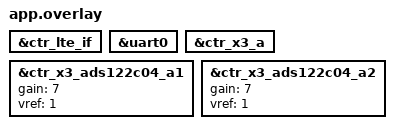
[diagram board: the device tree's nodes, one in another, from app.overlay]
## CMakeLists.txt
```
#
# Copyright (c) 2024 HARDWARIO a.s.
#
#  SPDX-License-Identifier: LicenseRef-HARDWARIO-5-Clause
#

cmake_minimum_required(VERSION 3.20.0)

set(ENV{FW_BUNDLE} "com.hardwario.chester.scale")
set(ENV{FW_VERSION} "v1.0.0")
set(ENV{FW_NAME} "CHESTER Scale")

find_package(Zephyr REQUIRED HINTS $ENV{ZEPHYR_BASE})

project(chester-scale)

target_sources(app PRIVATE src/main.c)
target_sources(app PRIVATE src/app_shell.c)
target_sources(app PRIVATE src/app_loop.c)
target_sources(app PRIVATE src/app_init.c)
target_sources(app PRIVATE src/app_data.c)
target_sources(app PRIVATE src/app_send.c)
target_sources(app PRIVATE src/app_config.c)
target_sources(app PRIVATE src/app_handler.c)
target_sources(app PRIVATE src/app_measure.c)
target_sources(app PRIVATE src/app_cbor.c)
```

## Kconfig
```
#
# Copyright (c) 2024 HARDWARIO a.s.
#
# SPDX-License-Identifier: LicenseRef-HARDWARIO-5-Clause
#

menu "Application"

# CHESTER SCALE Project | SCALE Variant 

# LTE 
config SHIELD_CTR_LTE
	bool "Enable SHIELD_CTR_LTE"
	default y 

config CTR_LTE
	default y
# X3_A 
config SHIELD_CTR_CTR_X3_A
	bool "Enable SHIELD_CTR_X3_A"
	default y 

config CTR_X3
	default y

endmenu

menu "Zephyr Kernel"
source "Kconfig.zephyr"
endmenu
```

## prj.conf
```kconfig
#
# Copyright (c) 2024 HARDWARIO a.s.
#
#  SPDX-License-Identifier: LicenseRef-HARDWARIO-5-Clause
#

# Configurations
CONFIG_ADC_SHELL=y
CONFIG_CTR_ACCEL=y
CONFIG_CTR_BATT=y
CONFIG_CTR_BLE=y
CONFIG_CTR_BUTTON=y
CONFIG_CTR_BUF=y
CONFIG_CTR_DEFAULTS=y
CONFIG_CTR_INFO=y
CONFIG_CTR_LED=y
CONFIG_CTR_LOG=y
CONFIG_CTR_RTC=y
CONFIG_CTR_THERM=y
CONFIG_CTR_WDOG=y
CONFIG_ENTROPY_GENERATOR=y
CONFIG_TINYCRYPT=y
CONFIG_TINYCRYPT_SHA256=y
CONFIG_ZCBOR=y
CONFIG_ZCBOR_STOP_ON_ERROR=y
CONFIG_CTR_LTE_CLKSYNC=y

# Extra configurations
CONFIG_ADC_TLA2021_INIT_PRIORITY=60
CONFIG_ADC_NRFX_SAADC=n
CONFIG_ADC_SHELL=n

# USER CODE BEGIN Config 
# USER CODE END Config
```

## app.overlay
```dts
/*
 * Copyright (c) 2024 HARDWARIO a.s.
 *
 * SPDX-License-Identifier: LicenseRef-HARDWARIO-5-Clause
 */

/* CHESTER SCALE Project | SCALE Variant */

/* LTE  */
&ctr_lte_if {
	status = "okay";
};

&uart0 {
	status = "okay";
};
/* X3_A  */
&ctr_x3_a {
	status = "okay";
};

&ctr_x3_ads122c04_a1 {
	status = "okay";
	gain = <7>;
	vref = <1>;
};

&ctr_x3_ads122c04_a2 {
	status = "okay";
	gain = <7>;
	vref = <1>;
};
```

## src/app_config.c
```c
/*
 * Copyright (c) 2024 HARDWARIO a.s.
 *
 * SPDX-License-Identifier: LicenseRef-HARDWARIO-5-Clause
 */

#include "app_config.h"

/* CHESTER includes */
#include <chester/ctr_config.h>

/* Zephyr includes */
#include <zephyr/init.h>
#include <zephyr/kernel.h>
#include <zephyr/logging/log.h>
#include <zephyr/settings/settings.h>
#include <zephyr/shell/shell.h>

/* Standard includes */
#include <ctype.h>
#include <stdbool.h>
#include <stdio.h>
#include <stdlib.h>
#include <string.h>

/* USER CODE BEGIN Includes */
/* USER CODE END Includes */

LOG_MODULE_REGISTER(app_config, LOG_LEVEL_DBG);

#define SETTINGS_PFX "chester-scale"

struct app_config g_app_config;

static struct app_config m_app_config_interim = {
	.channel_a1_active = true,
	.channel_a2_active = true,
	.channel_b1_active = true,
	.channel_b2_active = true,
	.weight_measurement_interval = 60,
	.report_interval = 900,
	.people_measurement_interval = 600,
	.people_counter_power_off_delay = 30,
	.people_counter_stay_timeout = 5,
	.people_counter_adult_border = 4,

	/* USER CODE BEGIN Struct Variables */
	/* USER CODE END Struct Variables */
};

/* USER CODE BEGIN Variables */
/* USER CODE END Variables */

static void print_channel_a1_active(const struct shell *shell)
{
	shell_print(shell, "app config channel-a1-active  %s",
			m_app_config_interim.channel_a1_active ? "true" : "false");
}

int app_config_cmd_config_channel_a1_active(const struct shell *shell, size_t argc, char **argv)
{
	if (argc == 1) {
		print_channel_a1_active(shell);                                                    
		return 0;
	}
	if (argc == 2) {
		bool is_false = !strcmp(argv[1], "false");
		bool is_true = !strcmp(argv[1], "true");
		if (is_false) {
			m_app_config_interim.channel_a1_active = false;
		} else if (is_true) {
			m_app_config_interim.channel_a1_active = true;
		} else {
			shell_error(shell, "invalid format");
			return -EINVAL;
		}
		return 0;
	}
	shell_help(shell);
	return -EINVAL;
}

static void print_channel_a2_active(const struct shell *shell)
{
	shell_print(shell, "app config channel-a2-active  %s",
			m_app_config_interim.channel_a2_active ? "true" : "false");
}

int app_config_cmd_config_channel_a2_active(const struct shell *shell, size_t argc, char **argv)
{
	if (argc == 1) {
		print_channel_a2_active(shell);                                                    
		return 0;
	}
	if (argc == 2) {
		bool is_false = !strcmp(argv[1], "false");
		bool is_true = !strcmp(argv[1], "true");
		if (is_false) {
			m_app_config_interim.channel_a2_active = false;
		} else if (is_true) {
			m_app_config_interim.channel_a2_active = true;
		} else {
			shell_error(shell, "invalid format");
			return -EINVAL;
		}
		return 0;
	}
	shell_help(shell);
	return -EINVAL;
}

static void print_channel_b1_active(const struct shell *shell)
{
	shell_print(shell, "app config channel-b1-active  %s",
			m_app_config_interim.channel_b1_active ? "true" : "false");
}

int app_config_cmd_config_channel_b1_active(const struct shell *shell, size_t argc, char **argv)
{
	if (argc == 1) {
		print_channel_b1_active(shell);                                                    
		return 0;
	}
	if (argc == 2) {
		bool is_false = !strcmp(argv[1], "false");
		bool is_true = !strcmp(argv[1], "true");
		if (is_false) {
			m_app_config_interim.channel_b1_active = false;
		} else if (is_true) {
			m_app_config_interim.channel_b1_active = true;
		} else {
			shell_error(shell, "invalid format");
			return -EINVAL;
		}
		return 0;
	}
	shell_help(shell);
	return -EINVAL;
}

static void print_channel_b2_active(const struct shell *shell)
{
	shell_print(shell, "app config channel-b2-active  %s",
			m_app_config_interim.channel_b2_active ? "true" : "false");
}

int app_config_cmd_config_channel_b2_active(const struct shell *shell, size_t argc, char **argv)
{
	if (argc == 1) {
		print_channel_b2_active(shell);                                                    
		return 0;
	}
	if (argc == 2) {
		bool is_false = !strcmp(argv[1], "false");
		bool is_true = !strcmp(argv[1], "true");
		if (is_false) {
			m_app_config_interim.channel_b2_active = false;
		} else if (is_true) {
			m_app_config_interim.channel_b2_active = true;
		} else {
			shell_error(shell, "invalid format");
			return -EINVAL;
		}
		return 0;
	}
	shell_help(shell);
	return -EINVAL;
}

static void print_weight_measurement_interval(const struct shell *shell)
{
	shell_print(shell, "app config weight-measurement-interval  %d",
			m_app_config_interim.weight_measurement_interval);
}

int app_config_cmd_config_weight_measurement_interval(const struct shell *shell, size_t argc, char **argv)
{
	if (argc == 1) {
		print_weight_measurement_interval(shell);
		return 0;
	}
	if (argc == 2) {
		size_t len = strlen(argv[1]);
		for (size_t i = 0; i < len; i++) {
			if (!isdigit((int)argv[1][i])) {
				shell_error(shell, "invalid format");
				return -EINVAL;
			}
		}
		long value = strtol(argv[1], NULL, 10);
		if (value < 5 || value > 3600) {
			shell_error(shell, "invalid range");
			return -EINVAL;
		}
		m_app_config_interim.weight_measurement_interval = (int)value;
		return 0;
	}
	shell_help(shell);
	return -EINVAL;
}

static void print_report_interval(const struct shell *shell)
{
	shell_print(shell, "app config report-interval  %d",
			m_app_config_interim.report_interval);
}

int app_config_cmd_config_report_interval(const struct shell *shell, size_t argc, char **argv)
{
	if (argc == 1) {
		print_report_interval(shell);
		return 0;
	}
	if (argc == 2) {
		size_t len = strlen(argv[1]);
		for (size_t i = 0; i < len; i++) {
			if (!isdigit((int)argv[1][i])) {
				shell_error(shell, "invalid format");
				return -EINVAL;
			}
		}
		long value = strtol(argv[1], NULL, 10);
		if (value < 30 || value > 86400) {
			shell_error(shell, "invalid range");
			return -EINVAL;
		}
		m_app_config_interim.report_interval = (int)value;
		return 0;
	}
	shell_help(shell);
	return -EINVAL;
}

static void print_people_measurement_interval(const struct shell *shell)
{
	shell_print(shell, "app config people-measurement-interval  %d",
			m_app_config_interim.people_measurement_interval);
}

int app_config_cmd_config_people_measurement_interval(const struct shell *shell, size_t argc, char **argv)
{
	if (argc == 1) {
		print_people_measurement_interval(shell);
		return 0;
	}
	if (argc == 2) {
		size_t len = strlen(argv[1]);
		for (size_t i = 0; i < len; i++) {
			if (!isdigit((int)argv[1][i])) {
				shell_error(shell, "invalid format");
				return -EINVAL;
			}
		}
		long value = strtol(argv[1], NULL, 10);
		if (value < 5 || value > 3600) {
			shell_error(shell, "invalid range");
			return -EINVAL;
		}
		m_app_config_interim.people_measurement_interval = (int)value;
		return 0;
	}
	shell_help(shell);
	return -EINVAL;
}

static void print_people_counter_power_off_delay(const struct shell *shell)
{
	shell_print(shell, "app config people-counter-power-off-delay  %d",
			m_app_config_interim.people_counter_power_off_delay);
}

int app_config_cmd_config_people_counter_power_off_delay(const struct shell *shell, size_t argc, char **argv)
{
	if (argc == 1) {
		print_people_counter_power_off_delay(shell);
		return 0;
	}
	if (argc == 2) {
		size_t len = strlen(argv[1]);
		for (size_t i = 0; i < len; i++) {
			if (!isdigit((int)argv[1][i])) {
				shell_error(shell, "invalid format");
				return -EINVAL;
			}
		}
		long value = strtol(argv[1], NULL, 10);
		if (value < 0 || value > 255) {
			shell_error(shell, "invalid range");
			return -EINVAL;
		}
		m_app_config_interim.people_counter_power_off_delay = (int)value;
		return 0;
	}
	shell_help(shell);
	return -EINVAL;
}

static void print_people_counter_stay_timeout(const struct shell *shell)
{
	shell_print(shell, "app config people-counter-stay-timeout  %d",
			m_app_config_interim.people_counter_stay_timeout);
}

int app_config_cmd_config_people_counter_stay_timeout(const struct shell *shell, size_t argc, char **argv)
{
	if (argc == 1) {
		print_people_counter_stay_timeout(shell);
		return 0;
	}
	if (argc == 2) {
		size_t len = strlen(argv[1]);
		for (size_t i = 0; i < len; i++) {
			if (!isdigit((int)argv[1][i])) {
				shell_error(shell, "invalid format");
				return -EINVAL;
			}
		}
		long value = strtol(argv[1], NULL, 10);
		if (value < 0 || value > 255) {
			shell_error(shell, "invalid range");
			return -EINVAL;
		}
		m_app_config_interim.people_counter_stay_timeout = (int)value;
		return 0;
	}
	shell_help(shell);
	return -EINVAL;
}

static void print_people_counter_adult_border(const struct shell *shell)
{
	shell_print(shell, "app config people-counter-adult-border  %d",
			m_app_config_interim.people_counter_adult_border);
}

int app_config_cmd_config_people_counter_adult_border(const struct shell *shell, size_t argc, char **argv)
{
	if (argc == 1) {
		print_people_counter_adult_border(shell);
		return 0;
	}
	if (argc == 2) {
		size_t len = strlen(argv[1]);
		for (size_t i = 0; i < len; i++) {
			if (!isdigit((int)argv[1][i])) {
				shell_error(shell, "invalid format");
				return -EINVAL;
			}
		}
		long value = strtol(argv[1], NULL, 10);
		if (value < 0 || value > 8) {
			shell_error(shell, "invalid range");
			return -EINVAL;
		}
		m_app_config_interim.people_counter_adult_border = (int)value;
		return 0;
	}
	shell_help(shell);
	return -EINVAL;
}

int app_config_cmd_config_show(const struct shell *shell, size_t argc, char **argv)
{
	print_channel_a1_active(shell);
	print_channel_a2_active(shell);
	print_channel_b1_active(shell);
	print_channel_b2_active(shell);
	print_weight_measurement_interval(shell);
	print_report_interval(shell);
	print_people_measurement_interval(shell);
	print_people_counter_power_off_delay(shell);
	print_people_counter_stay_timeout(shell);
	print_people_counter_adult_border(shell);
	
	return 0;
}

/* USER CODE BEGIN Functions 1 */
/* USER CODE END Functions 1 */

static int h_commit(void)
{
	LOG_DBG("Loaded settings in full");
	memcpy(&g_app_config, &m_app_config_interim, sizeof(g_app_config));

	return 0;
}

static int h_set(const char *key, size_t len, settings_read_cb read_cb, void *cb_arg) 
{
	int ret;
	const char *next;
	if (settings_name_steq(key, "channel-a1-active", &next) && !next) {
		if (len != sizeof(m_app_config_interim.channel_a1_active)) {
			return -EINVAL;
		}
		ret = read_cb(cb_arg, &m_app_config_interim.channel_a1_active, len);
		if (ret < 0) {
			LOG_ERR("Call `read_cb` failed: %d", ret);
			return ret;
		}
		return 0;
	}

	if (settings_name_steq(key, "channel-a2-active", &next) && !next) {
		if (len != sizeof(m_app_config_interim.channel_a2_active)) {
			return -EINVAL;
		}
		ret = read_cb(cb_arg, &m_app_config_interim.channel_a2_active, len);
		if (ret < 0) {
			LOG_ERR("Call `read_cb` failed: %d", ret);
			return ret;
		}
		return 0;
	}

	if (settings_name_steq(key, "channel-b1-active", &next) && !next) {
		if (len != sizeof(m_app_config_interim.channel_b1_active)) {
			return -EINVAL;
		}
		ret = read_cb(cb_arg, &m_app_config_interim.channel_b1_active, len);
		if (ret < 0) {
			LOG_ERR("Call `read_cb` failed: %d", ret);
			return ret;
		}
		return 0;
	}

	if (settings_name_steq(key, "channel-b2-active", &next) && !next) {
		if (len != sizeof(m_app_config_interim.channel_b2_active)) {
			return -EINVAL;
		}
		ret = read_cb(cb_arg, &m_app_config_interim.channel_b2_active, len);
		if (ret < 0) {
			LOG_ERR("Call `read_cb` failed: %d", ret);
			return ret;
		}
		return 0;
	}

	if (settings_name_steq(key, "weight-measurement-interval", &next) && !next) {
		if (len != sizeof(m_app_config_interim.weight_measurement_interval)) {
			return -EINVAL;
		}
		ret = read_cb(cb_arg, &m_app_config_interim.weight_measurement_interval, len);
		if (ret < 0) {
			LOG_ERR("Call `read_cb` failed: %d", ret);
			return ret;
		}
		return 0;
	}

	if (settings_name_steq(key, "report-interval", &next) && !next) {
		if (len != sizeof(m_app_config_interim.report_interval)) {
			return -EINVAL;
		}
		ret = read_cb(cb_arg, &m_app_config_interim.report_interval, len);
		if (ret < 0) {
			LOG_ERR("Call `read_cb` failed: %d", ret);
			return ret;
		}
		return 0;
	}

	if (settings_name_steq(key, "people-measurement-interval", &next) && !next) {
		if (len != sizeof(m_app_config_interim.people_measurement_interval)) {
			return -EINVAL;
		}
		ret = read_cb(cb_arg, &m_app_config_interim.people_measurement_interval, len);
		if (ret < 0) {
			LOG_ERR("Call `read_cb` failed: %d", ret);
			return ret;
		}
		return 0;
	}

	if (settings_name_steq(key, "people-counter-power-off-delay", &next) && !next) {
		if (len != sizeof(m_app_config_interim.people_counter_power_off_delay)) {
			return -EINVAL;
		}
		ret = read_cb(cb_arg, &m_app_config_interim.people_counter_power_off_delay, len);
		if (ret < 0) {
			LOG_ERR("Call `read_cb` failed: %d", ret);
			return ret;
		}
		return 0;
	}

	if (settings_name_steq(key, "people-counter-stay-timeout", &next) && !next) {
		if (len != sizeof(m_app_config_interim.people_counter_stay_timeout)) {
			return -EINVAL;
		}
		ret = read_cb(cb_arg, &m_app_config_interim.people_counter_stay_timeout, len);
		if (ret < 0) {
			LOG_ERR("Call `read_cb` failed: %d", ret);
			return ret;
		}
		return 0;
	}

	if (settings_name_steq(key, "people-counter-adult-border", &next) && !next) {
		if (len != sizeof(m_app_config_interim.people_counter_adult_border)) {
			return -EINVAL;
		}
		ret = read_cb(cb_arg, &m_app_config_interim.people_counter_adult_border, len);
		if (ret < 0) {
			LOG_ERR("Call `read_cb` failed: %d", ret);
			return ret;
		}
		return 0;
	}

	/* USER CODE BEGIN Functions 2 */
	/* USER CODE END Functions 2 */

	return 0;
}

static int h_export(int (*export_func)(const char *name, const void *val, size_t val_len))
{
	int ret;

	ret = export_func("chester-scale/channel-a1-active", &m_app_config_interim.channel_a1_active,
					  sizeof( m_app_config_interim.channel_a1_active));
	if (ret < 0) {
		return ret;
	}

	ret = export_func("chester-scale/channel-a2-active", &m_app_config_interim.channel_a2_active,
					  sizeof( m_app_config_interim.channel_a2_active));
	if (ret < 0) {
		return ret;
	}

	ret = export_func("chester-scale/channel-b1-active", &m_app_config_interim.channel_b1_active,
					  sizeof( m_app_config_interim.channel_b1_active));
	if (ret < 0) {
		return ret;
	}

	ret = export_func("chester-scale/channel-b2-active", &m_app_config_interim.channel_b2_active,
					  sizeof( m_app_config_interim.channel_b2_active));
	if (ret < 0) {
		return ret;
	}

	ret = export_func("chester-scale/weight-measurement-interval", &m_app_config_interim.weight_measurement_interval,
					  sizeof( m_app_config_interim.weight_measurement_interval));
	if (ret < 0) {
		return ret;
	}

	ret = export_func("chester-scale/report-interval", &m_app_config_interim.report_interval,
					  sizeof( m_app_config_interim.report_interval));
	if (ret < 0) {
		return ret;
	}

	ret = export_func("chester-scale/people-measurement-interval", &m_app_config_interim.people_measurement_interval,
					  sizeof( m_app_config_interim.people_measurement_interval));
	if (ret < 0) {
		return ret;
	}

	ret = export_func("chester-scale/people-counter-power-off-delay", &m_app_config_interim.people_counter_power_off_delay,
					  sizeof( m_app_config_interim.people_counter_power_off_delay));
	if (ret < 0) {
		return ret;
	}

	ret = export_func("chester-scale/people-counter-stay-timeout", &m_app_config_interim.people_counter_stay_timeout,
					  sizeof( m_app_config_interim.people_counter_stay_timeout));
	if (ret < 0) {
		return ret;
	}

	ret = export_func("chester-scale/people-counter-adult-border", &m_app_config_interim.people_counter_adult_border,
					  sizeof( m_app_config_interim.people_counter_adult_border));
	if (ret < 0) {
		return ret;
	}

	/* USER CODE BEGIN Functions 3 */
	/* USER CODE END Functions 3 */

	return 0;
}

static int init(void) 
{
	int ret;

	LOG_INF("System initialization");

	static struct settings_handler sh = {
		.name = SETTINGS_PFX,
		.h_set = h_set,
		.h_commit = h_commit,
		.h_export = h_export,
	};

	ret = settings_register(&sh);

	if (ret < 0) {
		LOG_ERR("Call `settings_register` failed: %d", ret);
		return ret;
	}

	ret = settings_load_subtree(SETTINGS_PFX);

	if (ret < 0) {
		LOG_ERR("Call `settings_load_subtree` failed: %d", ret);
		return ret;
	}

	ctr_config_append_show(SETTINGS_PFX, app_config_cmd_config_show);

	/* USER CODE BEGIN Functions 4 */
	/* USER CODE END Functions 4 */

	return 0;
}

SYS_INIT(init, APPLICATION, CONFIG_APPLICATION_INIT_PRIORITY);
```

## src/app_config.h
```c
/*
 * Copyright (c) 2024 HARDWARIO a.s.
 *
 * SPDX-License-Identifier: LicenseRef-HARDWARIO-5-Clause
 */

#ifndef APP_CONFIG_H_
#define APP_CONFIG_H_

/* Zephyr includes */
#include <zephyr/shell/shell.h>

/* Standard includes */
#include <stdbool.h>
#include <stddef.h>

/* USER CODE BEGIN Includes */
/* USER CODE END Includes */

#ifdef __cplusplus
extern "C" {
#endif

struct app_config {
	bool channel_a1_active;
	bool channel_a2_active;
	bool channel_b1_active;
	bool channel_b2_active;
	int weight_measurement_interval;
	int report_interval;
	int people_measurement_interval;
	int people_counter_power_off_delay;
	int people_counter_stay_timeout;
	int people_counter_adult_border;

	/* USER CODE BEGIN Struct Variables */
	/* USER CODE END Struct Variables */
};

extern struct app_config g_app_config;

/* USER CODE BEGIN Variables */
/* USER CODE END Variables */

int app_config_cmd_config_show(const struct shell *shell, size_t argc, char **argv);
int app_config_cmd_config_channel_a1_active(const struct shell *shell, size_t argc, char **argv);
int app_config_cmd_config_channel_a2_active(const struct shell *shell, size_t argc, char **argv);
int app_config_cmd_config_channel_b1_active(const struct shell *shell, size_t argc, char **argv);
int app_config_cmd_config_channel_b2_active(const struct shell *shell, size_t argc, char **argv);
int app_config_cmd_config_weight_measurement_interval(const struct shell *shell, size_t argc, char **argv);
int app_config_cmd_config_report_interval(const struct shell *shell, size_t argc, char **argv);
int app_config_cmd_config_people_measurement_interval(const struct shell *shell, size_t argc, char **argv);
int app_config_cmd_config_people_counter_power_off_delay(const struct shell *shell, size_t argc, char **argv);
int app_config_cmd_config_people_counter_stay_timeout(const struct shell *shell, size_t argc, char **argv);
int app_config_cmd_config_people_counter_adult_border(const struct shell *shell, size_t argc, char **argv);

/* USER CODE BEGIN Functions 1 */
/* USER CODE END Functions 1 */

#ifdef __cplusplus
}
#endif

#endif /* APP_CONFIG_H_ */
```

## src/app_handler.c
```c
/*
 * Copyright (c) 2023 HARDWARIO a.s.
 *
 * SPDX-License-Identifier: LicenseRef-HARDWARIO-5-Clause
 */

#include "app_data.h"
#include "app_handler.h"
#include "app_init.h"

/* CHESTER includes */
#include <chester/ctr_led.h>
#include <chester/ctr_lte.h>

/* Zephyr includes */
#include <zephyr/kernel.h>
#include <zephyr/logging/log.h>
#include <zephyr/sys/reboot.h>

/* Standard includes */
#include <stdbool.h>
#include <stddef.h>
#include <string.h>

LOG_MODULE_REGISTER(app_handler, LOG_LEVEL_DBG);

static void start(void)
{
	int ret;

	ret = ctr_lte_start(NULL);
	if (ret) {
		LOG_ERR("Call `ctr_lte_start` failed: %d", ret);
		k_oops();
	}
}

static void attach(void)
{
	int ret;

	ret = ctr_lte_attach(NULL);
	if (ret) {
		LOG_ERR("Call `ctr_lte_attach` failed: %d", ret);
		k_oops();
	}
}

void app_handler_lte(enum ctr_lte_event event, union ctr_lte_event_data *data, void *param)
{
	switch (event) {
	case CTR_LTE_EVENT_FAILURE:
		LOG_ERR("Event `CTR_LTE_EVENT_FAILURE`");
		start();
		break;

	case CTR_LTE_EVENT_START_OK:
		LOG_INF("Event `CTR_LTE_EVENT_START_OK`");
		attach();
		break;

	case CTR_LTE_EVENT_START_ERR:
		LOG_ERR("Event `CTR_LTE_EVENT_START_ERR`");
		start();
		break;

	case CTR_LTE_EVENT_ATTACH_OK:
		LOG_INF("Event `CTR_LTE_EVENT_ATTACH_OK`");
		k_sem_give(&g_app_init_sem);
		break;

	case CTR_LTE_EVENT_ATTACH_ERR:
		LOG_ERR("Event `CTR_LTE_EVENT_ATTACH_ERR`");
		start();
		break;

	case CTR_LTE_EVENT_DETACH_OK:
		LOG_INF("Event `CTR_LTE_EVENT_DETACH_OK`");
		break;

	case CTR_LTE_EVENT_DETACH_ERR:
		LOG_ERR("Event `CTR_LTE_EVENT_DETACH_ERR`");
		start();
		break;

	case CTR_LTE_EVENT_EVAL_OK:
		LOG_INF("Event `CTR_LTE_EVENT_EVAL_OK`");

		struct ctr_lte_eval *eval = &data->eval_ok.eval;

		LOG_DBG("EEST: %d", eval->eest);
		LOG_DBG("ECL: %d", eval->ecl);
		LOG_DBG("RSRP: %d", eval->rsrp);
		LOG_DBG("RSRQ: %d", eval->rsrq);
		LOG_DBG("SNR: %d", eval->snr);
		LOG_DBG("PLMN: %d", eval->plmn);
		LOG_DBG("CID: %d", eval->cid);
		LOG_DBG("BAND: %d", eval->band);
		LOG_DBG("EARFCN: %d", eval->earfcn);

		k_mutex_lock(&g_app_data_lte_eval_mut, K_FOREVER);
		memcpy(&g_app_data_lte_eval, &data->eval_ok.eval, sizeof(g_app_data_lte_eval));
		g_app_data_lte_eval_valid = true;
		k_mutex_unlock(&g_app_data_lte_eval_mut);

		break;

	case CTR_LTE_EVENT_EVAL_ERR:
		LOG_ERR("Event `CTR_LTE_EVENT_EVAL_ERR`");

		k_mutex_lock(&g_app_data_lte_eval_mut, K_FOREVER);
		g_app_data_lte_eval_valid = false;
		k_mutex_unlock(&g_app_data_lte_eval_mut);

		break;

	case CTR_LTE_EVENT_SEND_OK:
		LOG_INF("Event `CTR_LTE_EVENT_SEND_OK`");
		break;

	case CTR_LTE_EVENT_SEND_ERR:
		LOG_ERR("Event `CTR_LTE_EVENT_SEND_ERR`");
		start();
		break;

	default:
		LOG_WRN("Unknown event: %d", event);
		return;
	}
}

#if defined(CONFIG_CTR_BUTTON)

static void app_load_timer_handler(struct k_timer *timer)
{
	ctr_led_set(CTR_LED_CHANNEL_LOAD, 0);
}

K_TIMER_DEFINE(app_load_timer, app_load_timer_handler, NULL);

void app_handler_ctr_button(enum ctr_button_channel chan, enum ctr_button_event ev, int val,
			    void *user_data)
{
	int ret;

	if (chan != CTR_BUTTON_CHANNEL_INT) {
		return;
	}

	if (ev == CTR_BUTTON_EVENT_CLICK) {
		for (int i = 0; i < val; i++) {
			ret = ctr_led_set(CTR_LED_CHANNEL_Y, true);
			if (ret) {
				LOG_ERR("Call `ctr_led_set` failed: %d", ret);
				return;
			}

			k_sleep(K_MSEC(50));
			ret = ctr_led_set(CTR_LED_CHANNEL_Y, false);
			if (ret) {
				LOG_ERR("Call `ctr_led_set` failed: %d", ret);
				return;
			}

			k_sleep(K_MSEC(200));
		}

		switch (val) {
		case 4:
			sys_reboot(SYS_REBOOT_COLD);
			break;
		case 5:
			ret = ctr_led_set(CTR_LED_CHANNEL_LOAD, 1);
			if (ret) {
				LOG_ERR("Call `ctr_led_set` failed: %d", ret);
				return;
			}
			k_timer_start(&app_load_timer, K_MINUTES(2), K_FOREVER);
			break;
		}
	}
}

#endif /* defined(CONFIG_CTR_BUTTON) */
```

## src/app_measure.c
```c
/*
 * Copyright (c) 2023 HARDWARIO a.s.
 *
 * SPDX-License-Identifier: LicenseRef-HARDWARIO-5-Clause
 */

#include "app_config.h"
#include "app_data.h"
#include "app_loop.h"
#include "app_measure.h"

/* CHESTER includes */
#include <chester/ctr_accel.h>
#include <chester/ctr_rtc.h>
#include <chester/ctr_therm.h>
#include <chester/drivers/ctr_x3.h>
#include <chester/drivers/people_counter.h>

/* Zephyr includes */
#include <zephyr/device.h>
#include <zephyr/devicetree.h>
#include <zephyr/kernel.h>
#include <zephyr/shell/shell.h>

/* Standard includes */
#include <errno.h>
#include <limits.h>
#include <math.h>
#include <stdbool.h>
#include <stdint.h>
#include <stdlib.h>

LOG_MODULE_REGISTER(app_measure, LOG_LEVEL_DBG);

#define MAX_REPETITIONS 5
#define MAX_DIFFERENCE  100

K_MUTEX_DEFINE(g_app_measure_weight_lock);

static void weight_timer(struct k_timer *timer_id)
{
	LOG_INF("Weight timer expired");

	atomic_set(&g_app_loop_measure_weight, true);
	k_sem_give(&g_app_loop_sem);
}

K_TIMER_DEFINE(g_app_measure_weight_timer, weight_timer, NULL);

#if defined(CONFIG_SHIELD_CTR_X3_A) || defined(CONFIG_SHIELD_CTR_X3_B)

static int compare(const void *a, const void *b)
{
	int32_t sample_a = *(int32_t *)a;
	int32_t sample_b = *(int32_t *)b;

	if (sample_a == sample_b) {
		return 0;
	} else if (sample_a < sample_b) {
		return -1;
	}

	return 1;
}

enum measure_weight_slot {
	MEASURE_WEIGHT_SLOT_A,
	MEASURE_WEIGHT_SLOT_B,
};

static int read_weight(const char *id, enum measure_weight_slot slot, enum ctr_x3_channel channel,
		       int32_t *result)
{
	int ret;

#if defined(CONFIG_SHIELD_CTR_X3_A)
	static const struct device *ctr_x3_a_dev = DEVICE_DT_GET(DT_NODELABEL(ctr_x3_a));
#endif /* defined(CONFIG_SHIELD_CTR_X3_A) */

#if defined(CONFIG_SHIELD_CTR_X3_B)
	static const struct device *ctr_x3_b_dev = DEVICE_DT_GET(DT_NODELABEL(ctr_x3_b));
#endif /* defined(CONFIG_SHIELD_CTR_X3_B) */

	const struct device *dev;

	switch (slot) {
#if defined(CONFIG_SHIELD_CTR_X3_A)
	case MEASURE_WEIGHT_SLOT_A:
		dev = ctr_x3_a_dev;
		break;
#endif /* defined(CONFIG_SHIELD_CTR_X3_A) */
#if defined(CONFIG_SHIELD_CTR_X3_B)
	case MEASURE_WEIGHT_SLOT_B:
		dev = ctr_x3_b_dev;
		break;
#endif /* defined(CONFIG_SHIELD_CTR_X3_B) */
	default:
		LOG_ERR("Unknown slot: %d", slot);
		return -EINVAL;
	}

	if (!device_is_ready(dev)) {
		LOG_ERR("Device not ready");
		return -ENODEV;
	}

	ret = ctr_x3_set_power(dev, channel, true);
	if (ret) {
		LOG_ERR("Call `ctr_x3_set_power` failed: %d", ret);
		goto error;
	}

	k_sleep(K_MSEC(100));

	int32_t samples[32];
	int64_t average = 0;
	int64_t filtered = 0;

	for (size_t i = 0; i < ARRAY_SIZE(samples); i++) {
		int32_t sample;
		ret = ctr_x3_measure(dev, channel, &sample);
		if (ret) {
			LOG_ERR("Call `ctr_x3_measure` failed: %d", ret);
			goto error;
		}

		samples[i] = sample;
		average += sample;
	}

	average /= ARRAY_SIZE(samples);

	qsort(samples, ARRAY_SIZE(samples), sizeof(samples[0]), compare);

	size_t start = ARRAY_SIZE(samples) / 4;
	size_t stop = 3 * ARRAY_SIZE(samples) / 4;

	for (size_t i = start; i < stop; i++) {
		filtered += samples[i];
	}

	filtered /= stop - start;

	ret = ctr_x3_set_power(dev, channel, false);
	if (ret) {
		LOG_ERR("Call `ctr_x3_set_power` failed: %d", ret);
		goto error;
	}

	*result = filtered;

	LOG_DBG("Channel %s: Minimum: %" PRId32, id, samples[0]);
	LOG_DBG("Channel %s: Maximum: %" PRId32, id, samples[ARRAY_SIZE(samples) - 1]);
	LOG_DBG("Channel %s: Average: %" PRId32, id, (int32_t)average);
	LOG_DBG("Channel %s: Median: %" PRId32, id, samples[ARRAY_SIZE(samples) / 2]);
	LOG_DBG("Channel %s: Filtered: %" PRId32, id, (int32_t)filtered);

	return 0;

error:
	ctr_x3_set_power(dev, CTR_X3_CHANNEL_1, false);
	return ret;
}

static int filter_weight(const char *id, enum measure_weight_slot slot, enum ctr_x3_channel channel,
			 int32_t *result, int32_t *prev)
{
	int ret;

	int i;
	for (i = 0; i < MAX_REPETITIONS; i++) {
		if (i != 0) {
			LOG_INF("Channel %s: Repeating measurement (%d)", id, i);
		}

		ret = read_weight(id, slot, channel, result);
		if (ret) {
			LOG_ERR("Call `read_weight` failed: %d", ret);
			return ret;
		}

		if (*prev == INT32_MAX) {
			break;
		}

		int32_t diff = MAX(*result, *prev) - MIN(*result, *prev);

		if (diff < MAX_DIFFERENCE) {
			break;
		} else {
			*prev = *result;
		}
	}

	*prev = *result;

	if (i == MAX_REPETITIONS) {
		*result ^= BIT(30);
		LOG_WRN("Channel %s: Inverted ERROR flag (bit 30)", id);
	}

	return 0;
}

#endif /* defined(CONFIG_SHIELD_CTR_X3_A) || defined(CONFIG_SHIELD_CTR_X3_B) */

int app_measure_weight(void)
{
	int ret;

	k_timer_start(&g_app_measure_weight_timer,
		      K_MSEC(g_app_config.weight_measurement_interval * 1000), K_FOREVER);

	if (g_app_data.weight_measurement_count >= ARRAY_SIZE(g_app_data.weight_measurements)) {
		LOG_WRN("Weight measurements buffer full");
		return -ENOSPC;
	}

	int64_t timestamp;
	ret = ctr_rtc_get_ts(&timestamp);
	if (ret) {
		LOG_ERR("Call `ctr_rtc_get_ts` failed: %d", ret);
		return ret;
	}

	k_mutex_lock(&g_app_measure_weight_lock, K_FOREVER);

	int32_t a1_raw = INT32_MAX;
	int32_t a2_raw = INT32_MAX;
	int32_t b1_raw = INT32_MAX;
	int32_t b2_raw = INT32_MAX;

#if defined(CONFIG_SHIELD_CTR_X3_A)
	if (g_app_config.channel_a1_active) {
		static int32_t a1_raw_prev = INT32_MAX;
		ret = filter_weight("A1", MEASURE_WEIGHT_SLOT_A, CTR_X3_CHANNEL_1, &a1_raw,
				    &a1_raw_prev);
		if (ret) {
			LOG_ERR("Call `filter_weight` failed (A1): %d", ret);
			a1_raw = INT32_MAX;
		}
	}
#endif

#if defined(CONFIG_SHIELD_CTR_X3_A)
	if (g_app_config.channel_a2_active) {
		static int32_t a2_raw_prev = INT32_MAX;
		ret = filter_weight("A2", MEASURE_WEIGHT_SLOT_A, CTR_X3_CHANNEL_2, &a2_raw,
				    &a2_raw_prev);
		if (ret) {
			LOG_ERR("Call `filter_weight` failed (A2): %d", ret);
			a2_raw = INT32_MAX;
		}
	}
#endif

#if defined(CONFIG_SHIELD_CTR_X3_B)
	if (g_app_config.channel_b1_active) {
		static int32_t b1_raw_prev = INT32_MAX;
		ret = filter_weight("B1", MEASURE_WEIGHT_SLOT_B, CTR_X3_CHANNEL_1, &b1_raw,
				    &b1_raw_prev);
		if (ret) {
			LOG_ERR("Call `filter_weight` failed (B1): %d", ret);
			b1_raw = INT32_MAX;
		}
	}
#endif

#if defined(CONFIG_SHIELD_CTR_X3_B)
	if (g_app_config.channel_b2_active) {
		static int32_t b2_raw_prev = INT32_MAX;
		ret = filter_weight("B2", MEASURE_WEIGHT_SLOT_B, CTR_X3_CHANNEL_2, &b2_raw,
				    &b2_raw_prev);
		if (ret) {
			LOG_ERR("Call `filter_weight` failed (B2): %d", ret);
			b2_raw = INT32_MAX;
		}
	}
#endif

	k_mutex_unlock(&g_app_measure_weight_lock);

	g_app_data.weight_measurements[g_app_data.weight_measurement_count].timestamp_offset =
		timestamp - g_app_data.weight_measurement_timestamp;

	g_app_data.weight_measurements[g_app_data.weight_measurement_count].a1_raw = a1_raw;
	g_app_data.weight_measurements[g_app_data.weight_measurement_count].a2_raw = a2_raw;
	g_app_data.weight_measurements[g_app_data.weight_measurement_count].b1_raw = b1_raw;
	g_app_data.weight_measurements[g_app_data.weight_measurement_count].b2_raw = b2_raw;

	g_app_data.weight_measurement_count++;

	return 0;
}

#if defined(CONFIG_SHIELD_PEOPLE_COUNTER)

static void people_timer(struct k_timer *timer_id)
{
	LOG_INF("People timer expired");

	atomic_set(&g_app_loop_measure_people, true);
	k_sem_give(&g_app_loop_sem);
}

K_TIMER_DEFINE(g_app_measure_people_timer, people_timer, NULL);

int app_measure_people(void)
{
	int ret;

	k_timer_start(&g_app_measure_people_timer,
		      K_MSEC(g_app_config.people_measurement_interval * 1000), K_FOREVER);

	if (g_app_data.people_measurement_count >= ARRAY_SIZE(g_app_data.people_measurements)) {
		LOG_WRN("People measurements buffer full");
		return -ENOSPC;
	}

	int64_t timestamp;
	ret = ctr_rtc_get_ts(&timestamp);
	if (ret) {
		LOG_ERR("Call `ctr_rtc_get_ts` failed: %d", ret);
		return ret;
	}

	static const struct device *dev = DEVICE_DT_GET(DT_NODELABEL(people_counter));

	if (!device_is_ready(dev)) {
		LOG_ERR("Device not ready");
		return -ENODEV;
	}

	g_app_data.people_measurements[g_app_data.people_measurement_count].timestamp_offset =
		timestamp - g_app_data.people_measurement_timestamp;

	struct people_counter_measurement measurement;
	ret = people_counter_read_measurement(dev, &measurement);
	if (ret) {
		LOG_ERR("Call `people_counter_read_measurement` failed: %d", ret);

		g_app_data.people_measurements[g_app_data.people_measurement_count].is_valid =
			false;

	} else {
		LOG_INF("Motion counter: %u", measurement.motion_counter);
		LOG_INF("Pass counter (adult): %u", measurement.pass_counter_adult);
		LOG_INF("Pass counter (child): %u", measurement.pass_counter_child);
		LOG_INF("Stay counter (adult): %u", measurement.stay_counter_adult);
		LOG_INF("Stay counter (child): %u", measurement.stay_counter_child);
		LOG_INF("Total time (adult): %u", measurement.total_time_adult);
		LOG_INF("Total time (child): %u", measurement.total_time_child);
		LOG_INF("Consumed energy: %u", measurement.consumed_energy);

		g_app_data.people_measurements[g_app_data.people_measurement_count].measurement =
			measurement;

		g_app_data.people_measurements[g_app_data.people_measurement_count].is_valid = true;
	}

	g_app_data.people_measurement_count++;

	return 0;
}

#endif /* defined(CONFIG_SHIELD_PEOPLE_COUNTER) */

int app_measure(void)
{
	int ret;

#if defined(CONFIG_CTR_THERM)
	ret = ctr_therm_read(&g_app_data.therm_temperature);
	if (ret) {
		LOG_ERR("Call `ctr_therm_read` failed: %d", ret);
		g_app_data.therm_temperature = NAN;
	}
#endif

	ret = ctr_accel_read(&g_app_data.acceleration_x, &g_app_data.acceleration_y,
			     &g_app_data.acceleration_z, &g_app_data.orientation);
	if (ret) {
		LOG_ERR("Call `ctr_accel_read` failed: %d", ret);
		g_app_data.acceleration_x = NAN;
		g_app_data.acceleration_y = NAN;
		g_app_data.acceleration_z = NAN;
		g_app_data.orientation = INT_MAX;
	}

	return 0;
}

static int cmd_test(const struct shell *shell, size_t argc, char **argv)
{
#if defined(CONFIG_SHIELD_CTR_X3_A) || defined(CONFIG_SHIELD_CTR_X3_B)
	int ret;
#endif /* defined(CONFIG_SHIELD_CTR_X3_A) || defined(CONFIG_SHIELD_CTR_X3_B) */

	if (argc > 1) {
		shell_error(shell, "unknown parameter: %s", argv[1]);
		shell_help(shell);
		return -EINVAL;
	}

	k_mutex_lock(&g_app_measure_weight_lock, K_FOREVER);

	int32_t a1_raw = INT32_MAX;
	int32_t a2_raw = INT32_MAX;
	int32_t b1_raw = INT32_MAX;
	int32_t b2_raw = INT32_MAX;

#if defined(CONFIG_SHIELD_CTR_X3_A)
	static int32_t a1_raw_prev = INT32_MAX;
	ret = filter_weight("A1", MEASURE_WEIGHT_SLOT_A, CTR_X3_CHANNEL_1, &a1_raw, &a1_raw_prev);
	if (ret) {
		LOG_ERR("Call `filter_weight` failed (A1): %d", ret);
		shell_error(shell, "channel measurement failed (a1)");
		a1_raw = INT32_MAX;
	}
#endif

	if (a1_raw == INT32_MAX) {
		shell_print(shell, "raw (a1): (null)");
	} else {
		shell_print(shell, "raw (a1): %" PRId32, a1_raw);
	}

#if defined(CONFIG_SHIELD_CTR_X3_A)
	static int32_t a2_raw_prev = INT32_MAX;
	ret = filter_weight("A2", MEASURE_WEIGHT_SLOT_A, CTR_X3_CHANNEL_2, &a2_raw, &a2_raw_prev);
	if (ret) {
		LOG_ERR("Call `filter_weight` failed (A2): %d", ret);
		shell_error(shell, "channel measurement failed (a2)");
		a2_raw = INT32_MAX;
	}
#endif

	if (a2_raw == INT32_MAX) {
		shell_print(shell, "raw (a2): (null)");
	} else {
		shell_print(shell, "raw (a2): %" PRId32, a2_raw);
	}

#if defined(CONFIG_SHIELD_CTR_X3_B)
	static int32_t b1_raw_prev = INT32_MAX;
	ret = filter_weight("B1", MEASURE_WEIGHT_SLOT_B, CTR_X3_CHANNEL_1, &b1_raw, &b1_raw_prev);
	if (ret) {
		LOG_ERR("Call `filter_weight` failed (B1): %d", ret);
		shell_error(shell, "channel measurement failed (b1)");
		b1_raw = INT32_MAX;
	}
#endif

	if (b1_raw == INT32_MAX) {
		shell_print(shell, "raw (b1): (null)");
	} else {
		shell_print(shell, "raw (b1): %" PRId32, b1_raw);
	}

#if defined(CONFIG_SHIELD_CTR_X3_B)
	static int32_t b2_raw_prev = INT32_MAX;
	ret = filter_weight("B2", MEASURE_WEIGHT_SLOT_B, CTR_X3_CHANNEL_2, &b2_raw, &b2_raw_prev);
	if (ret) {
		LOG_ERR("Call `filter_weight` failed (B2): %d", ret);
		shell_error(shell, "channel measurement failed (b2)");
		b2_raw = INT32_MAX;
	}
#endif

	if (b2_raw == INT32_MAX) {
		shell_print(shell, "raw (b2): (null)");
	} else {
		shell_print(shell, "raw (b2): %" PRId32, b2_raw);
	}

	k_mutex_unlock(&g_app_measure_weight_lock);

	return 0;
}

SHELL_CMD_REGISTER(test, NULL, "Perform test measurement.", cmd_test);
```

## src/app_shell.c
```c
/*
 * Copyright (c) 2024 HARDWARIO a.s.
 *
 * SPDX-License-Identifier: LicenseRef-HARDWARIO-5-Clause
 */

#include "app_config.h"
#include "app_measure.h"
#include "app_send.h"

/* Zephyr includes */
#include <zephyr/kernel.h>
#include <zephyr/logging/log.h>
#include <zephyr/shell/shell.h>

/* Standard includes */
#include <errno.h>
#include <stdlib.h>

/* USER CODE BEGIN Includes */
/* USER CODE END Includes */

LOG_MODULE_REGISTER(app_shell, LOG_LEVEL_INF);

static int cmd_measure(const struct shell *shell, size_t argc, char **argv)
{
	if (argc > 1) {
		shell_error(shell, "unknown parameter: %s", argv[1]);
		shell_help(shell);
		return -EINVAL;
	}

	k_timer_start(&g_app_measure_weight_timer, K_NO_WAIT, K_FOREVER);

	return 0;
}

static int cmd_send(const struct shell *shell, size_t argc, char **argv)
{
	if (argc > 1) {
		shell_error(shell, "unknown parameter: %s", argv[1]);
		shell_help(shell);
		return -EINVAL;
	}

	app_send();

	return 0;
}

static int print_help(const struct shell *shell, size_t argc, char **argv)
{
	if (argc > 1) {
		shell_error(shell, "command not found: %s", argv[1]);
		shell_help(shell);
		return -EINVAL;
	}

	shell_help(shell);
	return 0;
}

/* clang-format off */

SHELL_STATIC_SUBCMD_SET_CREATE(
	sub_app_config,
   
	SHELL_CMD_ARG(show, NULL,
				  "List current configuration.",
				  app_config_cmd_config_show, 1, 0),
	
	SHELL_CMD_ARG(channel-a1-active, NULL,
				  "Get/Set channel A1 activation (format: <true|false>).",
				  app_config_cmd_config_channel_a1_active, 1, 1),
	
	SHELL_CMD_ARG(channel-a2-active, NULL,
				  "Get/Set channel A2 activation (format: <true|false>).",
				  app_config_cmd_config_channel_a2_active, 1, 1),
	
	SHELL_CMD_ARG(channel-b1-active, NULL,
				  "Get/Set channel B1 activation (format: <true|false>).",
				  app_config_cmd_config_channel_b1_active, 1, 1),
	
	SHELL_CMD_ARG(channel-b2-active, NULL,
				  "Get/Set channel B2 activation (format: <true|false>).",
				  app_config_cmd_config_channel_b2_active, 1, 1),
	
	SHELL_CMD_ARG(weight-measurement-interval, NULL,
				  "Get/Set weight measurement interval in seconds (format: <5-3600>).",
				  app_config_cmd_config_weight_measurement_interval, 1, 1),
	
	SHELL_CMD_ARG(report-interval, NULL,
				  "Get/Set report interval in seconds (format: <30-86400>).",
				  app_config_cmd_config_report_interval, 1, 1),
	
	SHELL_CMD_ARG(people-measurement-interval, NULL,
				  "Get/Set people measurement interval in seconds (format: <5-3600>).",
				  app_config_cmd_config_people_measurement_interval, 1, 1),
	
	SHELL_CMD_ARG(people-counter-power-off-delay, NULL,
				  "Get/Set People Counter power off delay in seconds (format: <0-255>).",
				  app_config_cmd_config_people_counter_power_off_delay, 1, 1),
	
	SHELL_CMD_ARG(people-counter-stay-timeout, NULL,
				  "Get/Set People Counter stay timeout in seconds (format: <0-255>).",
				  app_config_cmd_config_people_counter_stay_timeout, 1, 1),
	
	SHELL_CMD_ARG(people-counter-adult-border, NULL,
				  "Get/Set People Counter adult border (format: <0-8>).",
				  app_config_cmd_config_people_counter_adult_border, 1, 1),
	
	/* USER CODE BEGIN Functions 1 */
	/* USER CODE END Functions 1 */

	SHELL_SUBCMD_SET_END
);

SHELL_STATIC_SUBCMD_SET_CREATE(
	sub_app,

	SHELL_CMD_ARG(config, &sub_app_config, "Configuration commands.",
				  print_help, 1, 0),
		
	SHELL_SUBCMD_SET_END

	/* USER CODE BEGIN Functions 2 */
	/* USER CODE END Functions 2 */
);

SHELL_CMD_REGISTER(app, &sub_app, "Application commands.", print_help);

SHELL_CMD_REGISTER(send, NULL,"Send data immediately.", cmd_send);
SHELL_CMD_REGISTER(measure, NULL, "Start measurement immediately.", cmd_measure);


/* USER CODE BEGIN Functions 3 */
/* USER CODE END Functions 3 */

/* clang-format on */
```
